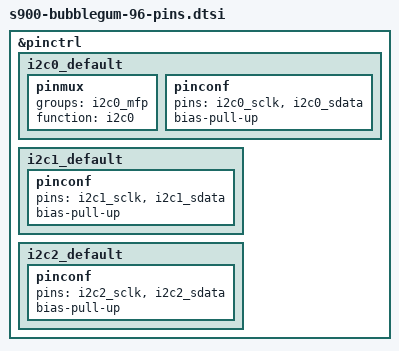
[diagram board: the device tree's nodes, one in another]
// SPDX-License-Identifier: (GPL-2.0+ OR MIT)

&pinctrl {

	i2c0_default: i2c0_default {
		pinmux {
			groups = "i2c0_mfp";
			function = "i2c0";
		};
		pinconf {
			pins = "i2c0_sclk", "i2c0_sdata";
			bias-pull-up;
		};
	};

	i2c1_default: i2c1_default {
		pinconf {
			pins = "i2c1_sclk", "i2c1_sdata";
			bias-pull-up;
		};
	};

	i2c2_default: i2c2_default {
		pinconf {
			pins = "i2c2_sclk", "i2c2_sdata";
			bias-pull-up;
		};
	};
};
